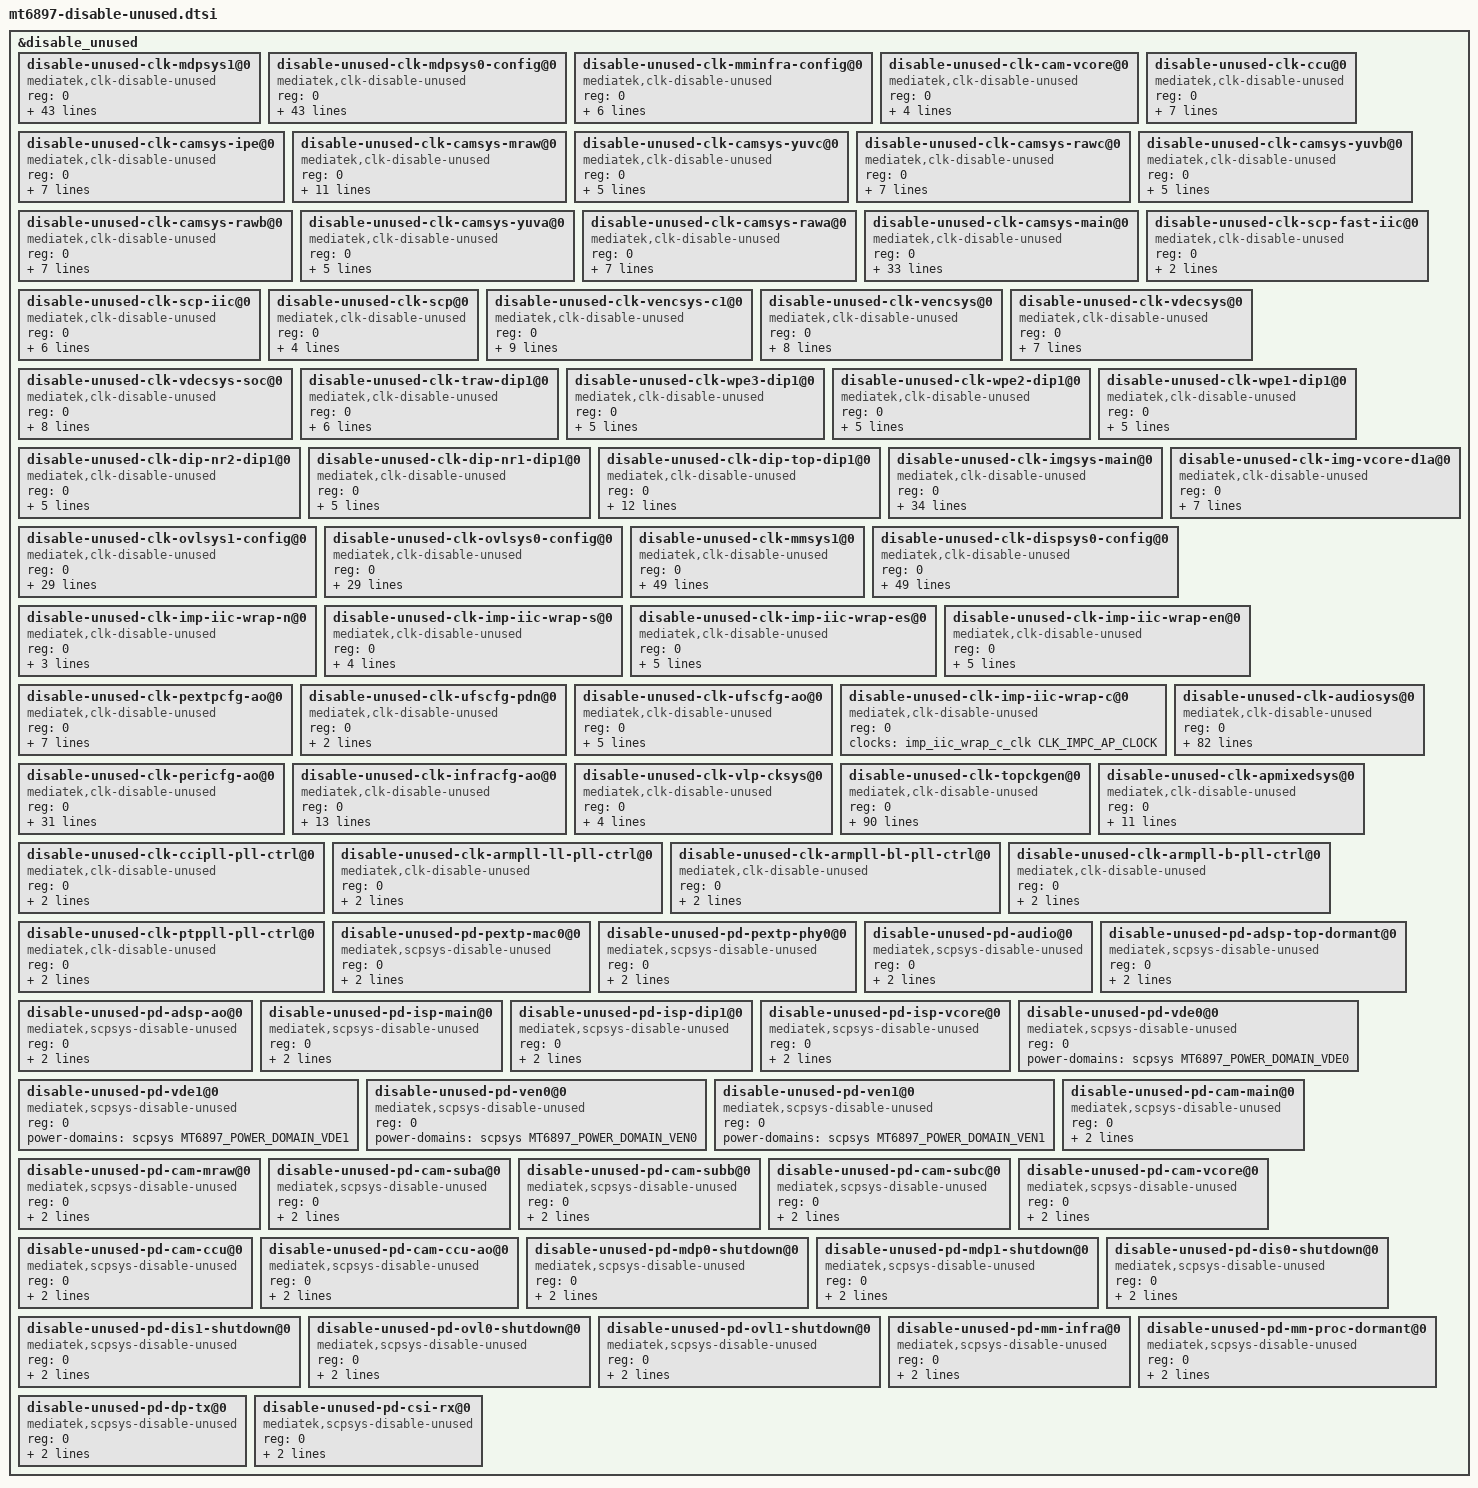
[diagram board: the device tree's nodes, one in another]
// SPDX-License-Identifier: (GPL-2.0 OR MIT)
/*
 * Copyright (C) 2023 MediaTek Inc.
 * Author: Benjamin Chao <benjamin.chao@mediatek.com>
 */

&disable_unused {
	status = "okay";
	disable-unused-clk-mdpsys1@0 {
		compatible = "mediatek,clk-disable-unused";
		reg = <0>;
		clocks =
			<&mdpsys1_config_clk CLK_MDP1_MDP_MUTEX0>,
			<&mdpsys1_config_clk CLK_MDP1_APB_BUS>,
			<&mdpsys1_config_clk CLK_MDP1_SMI0>,
			<&mdpsys1_config_clk CLK_MDP1_MDP_RDMA0>,
			<&mdpsys1_config_clk CLK_MDP1_MDP_RDMA2>,
			<&mdpsys1_config_clk CLK_MDP1_MDP_HDR0>,
			<&mdpsys1_config_clk CLK_MDP1_MDP_AAL0>,
			<&mdpsys1_config_clk CLK_MDP1_MDP_RSZ0>,
			<&mdpsys1_config_clk CLK_MDP1_MDP_TDSHP0>,
			<&mdpsys1_config_clk CLK_MDP1_MDP_COLOR0>,
			<&mdpsys1_config_clk CLK_MDP1_MDP_WROT0>,
			<&mdpsys1_config_clk CLK_MDP1_MDP_FAKE_ENG0>,
			<&mdpsys1_config_clk CLK_MDP1_MDP_DLI_ASYNC0>,
			<&mdpsys1_config_clk CLK_MDP1_MDP_DLI_ASYNC1>,
			<&mdpsys1_config_clk CLK_MDP1_MDPSYS_CONFIG>,
			<&mdpsys1_config_clk CLK_MDP1_MDP_RDMA1>,
			<&mdpsys1_config_clk CLK_MDP1_MDP_RDMA3>,
			<&mdpsys1_config_clk CLK_MDP1_MDP_HDR1>,
			<&mdpsys1_config_clk CLK_MDP1_MDP_AAL1>,
			<&mdpsys1_config_clk CLK_MDP1_MDP_RSZ1>,
			<&mdpsys1_config_clk CLK_MDP1_MDP_TDSHP1>,
			<&mdpsys1_config_clk CLK_MDP1_MDP_COLOR1>,
			<&mdpsys1_config_clk CLK_MDP1_MDP_WROT1>,
			<&mdpsys1_config_clk CLK_MDP1_MDP_FG0>,
			<&mdpsys1_config_clk CLK_MDP1_MDP_RSZ2>,
			<&mdpsys1_config_clk CLK_MDP1_MDP_WROT2>,
			<&mdpsys1_config_clk CLK_MDP1_MDP_DLO_ASYNC0>,
			<&mdpsys1_config_clk CLK_MDP1_MDP_FG1>,
			<&mdpsys1_config_clk CLK_MDP1_MDP_RSZ3>,
			<&mdpsys1_config_clk CLK_MDP1_MDP_WROT3>,
			<&mdpsys1_config_clk CLK_MDP1_MDP_DLO_ASYNC1>,
			<&mdpsys1_config_clk CLK_MDP1_MDP_DLI_ASYNC2>,
			<&mdpsys1_config_clk CLK_MDP1_MDP_DLI_ASYNC3>,
			<&mdpsys1_config_clk CLK_MDP1_MDP_DLO_ASYNC2>,
			<&mdpsys1_config_clk CLK_MDP1_MDP_DLO_ASYNC3>,
			<&mdpsys1_config_clk CLK_MDP1_MDP_BIRSZ0>,
			<&mdpsys1_config_clk CLK_MDP1_MDP_BIRSZ1>,
			<&mdpsys1_config_clk CLK_MDP1_IMG_DL_ASYNC0>,
			<&mdpsys1_config_clk CLK_MDP1_IMG_DL_ASYNC1>,
			<&mdpsys1_config_clk CLK_MDP1_HRE_TOP_MDPSYS>;
			power-domains = <&scpsys MT6897_POWER_DOMAIN_MDP1_SHUTDOWN>;
	};

	disable-unused-clk-mdpsys0-config@0 {
		compatible = "mediatek,clk-disable-unused";
		reg = <0>;
		clocks =
			<&mdpsys0_config_clk CLK_MDP0_MDP_MUTEX0>,
			<&mdpsys0_config_clk CLK_MDP0_APB_BUS>,
			<&mdpsys0_config_clk CLK_MDP0_SMI0>,
			<&mdpsys0_config_clk CLK_MDP0_MDP_RDMA0>,
			<&mdpsys0_config_clk CLK_MDP0_MDP_RDMA2>,
			<&mdpsys0_config_clk CLK_MDP0_MDP_HDR0>,
			<&mdpsys0_config_clk CLK_MDP0_MDP_AAL0>,
			<&mdpsys0_config_clk CLK_MDP0_MDP_RSZ0>,
			<&mdpsys0_config_clk CLK_MDP0_MDP_TDSHP0>,
			<&mdpsys0_config_clk CLK_MDP0_MDP_COLOR0>,
			<&mdpsys0_config_clk CLK_MDP0_MDP_WROT0>,
			<&mdpsys0_config_clk CLK_MDP0_MDP_FAKE_ENG0>,
			<&mdpsys0_config_clk CLK_MDP0_MDP_DLI_ASYNC0>,
			<&mdpsys0_config_clk CLK_MDP0_MDP_DLI_ASYNC1>,
			<&mdpsys0_config_clk CLK_MDP0_MDPSYS_CONFIG>,
			<&mdpsys0_config_clk CLK_MDP0_MDP_RDMA1>,
			<&mdpsys0_config_clk CLK_MDP0_MDP_RDMA3>,
			<&mdpsys0_config_clk CLK_MDP0_MDP_HDR1>,
			<&mdpsys0_config_clk CLK_MDP0_MDP_AAL1>,
			<&mdpsys0_config_clk CLK_MDP0_MDP_RSZ1>,
			<&mdpsys0_config_clk CLK_MDP0_MDP_TDSHP1>,
			<&mdpsys0_config_clk CLK_MDP0_MDP_COLOR1>,
			<&mdpsys0_config_clk CLK_MDP0_MDP_WROT1>,
			<&mdpsys0_config_clk CLK_MDP0_MDP_FG0>,
			<&mdpsys0_config_clk CLK_MDP0_MDP_RSZ2>,
			<&mdpsys0_config_clk CLK_MDP0_MDP_WROT2>,
			<&mdpsys0_config_clk CLK_MDP0_MDP_DLO_ASYNC0>,
			<&mdpsys0_config_clk CLK_MDP0_MDP_FG1>,
			<&mdpsys0_config_clk CLK_MDP0_MDP_RSZ3>,
			<&mdpsys0_config_clk CLK_MDP0_MDP_WROT3>,
			<&mdpsys0_config_clk CLK_MDP0_MDP_DLO_ASYNC1>,
			<&mdpsys0_config_clk CLK_MDP0_MDP_DLI_ASYNC2>,
			<&mdpsys0_config_clk CLK_MDP0_MDP_DLI_ASYNC3>,
			<&mdpsys0_config_clk CLK_MDP0_MDP_DLO_ASYNC2>,
			<&mdpsys0_config_clk CLK_MDP0_MDP_DLO_ASYNC3>,
			<&mdpsys0_config_clk CLK_MDP0_MDP_BIRSZ0>,
			<&mdpsys0_config_clk CLK_MDP0_MDP_BIRSZ1>,
			<&mdpsys0_config_clk CLK_MDP0_IMG_DL_ASYNC0>,
			<&mdpsys0_config_clk CLK_MDP0_IMG_DL_ASYNC1>,
			<&mdpsys0_config_clk CLK_MDP0_HRE_TOP_MDPSYS>;
			power-domains = <&scpsys MT6897_POWER_DOMAIN_MDP0_SHUTDOWN>;
	};

	disable-unused-clk-mminfra-config@0 {
		compatible = "mediatek,clk-disable-unused";
		reg = <0>;
		clocks =
			<&mminfra_config_clk CLK_MMINFRA_GCE_D>,
			<&mminfra_config_clk CLK_MMINFRA_GCE_M>,
			<&mminfra_config_clk CLK_MMINFRA_SMI>,
			<&mminfra_config_clk CLK_MMINFRA_GCE_26M>;
			power-domains = <&scpsys MT6897_POWER_DOMAIN_MM_INFRA>;
	};

	disable-unused-clk-cam-vcore@0 {
		compatible = "mediatek,clk-disable-unused";
		reg = <0>;
		clocks =
			<&cam_vcore_clk CLK_CAM_VCORE_MM0_SUBCOMMON_DCM_DIS>;
		power-domains = <&scpsys MT6897_POWER_DOMAIN_CAM_VCORE>;
	};

	disable-unused-clk-ccu@0 {
		compatible = "mediatek,clk-disable-unused";
		reg = <0>;
		clocks =
			<&ccu_main_clk CLK_CCU_LARB30_CON>,
			<&ccu_main_clk CLK_CCU_AHB_CON>,
			<&ccu_main_clk CLK_CCUSYS_CCU0_CON>,
			<&ccu_main_clk CLK_CCUSYS_CCU1_CON>,
			<&ccu_main_clk CLK_CCU2MM0_GALS_CON>;
			power-domains = <&scpsys MT6897_POWER_DOMAIN_CAM_CCU>;
	};

	disable-unused-clk-camsys-ipe@0 {
		compatible = "mediatek,clk-disable-unused";
		reg = <0>;
		clocks =
			<&camsys_ipe_clk CLK_CAMSYS_IPE_LARB19>,
			<&camsys_ipe_clk CLK_CAMSYS_IPE_DPE>,
			<&camsys_ipe_clk CLK_CAMSYS_IPE_FUS>,
			<&camsys_ipe_clk CLK_CAMSYS_IPE_DHZE>,
			<&camsys_ipe_clk CLK_CAMSYS_IPE_GALS>;
			power-domains = <&scpsys MT6897_POWER_DOMAIN_CAM_MRAW>;
	};

	disable-unused-clk-camsys-mraw@0 {
		compatible = "mediatek,clk-disable-unused";
		reg = <0>;
		clocks =
			<&camsys_mraw_clk CLK_CAM_MR_LARBX>,
			<&camsys_mraw_clk CLK_CAM_MR_GALS>,
			<&camsys_mraw_clk CLK_CAM_MR_CAMTG>,
			<&camsys_mraw_clk CLK_CAM_MR_MRAW0>,
			<&camsys_mraw_clk CLK_CAM_MR_MRAW1>,
			<&camsys_mraw_clk CLK_CAM_MR_MRAW2>,
			<&camsys_mraw_clk CLK_CAM_MR_MRAW3>,
			<&camsys_mraw_clk CLK_CAM_MR_PDA0>,
			<&camsys_mraw_clk CLK_CAM_MR_PDA1>;
			power-domains = <&scpsys MT6897_POWER_DOMAIN_CAM_MRAW>;
	};

	disable-unused-clk-camsys-yuvc@0 {
		compatible = "mediatek,clk-disable-unused";
		reg = <0>;
		clocks =
			<&camsys_yuvc_clk CLK_CAM_YC_LARBX>,
			<&camsys_yuvc_clk CLK_CAM_YC_CAM>,
			<&camsys_yuvc_clk CLK_CAM_YC_CAMTG>;
			power-domains = <&scpsys MT6897_POWER_DOMAIN_CAM_SUBC>;
	};

	disable-unused-clk-camsys-rawc@0 {
		compatible = "mediatek,clk-disable-unused";
		reg = <0>;
		clocks =
			<&camsys_rawc_clk CLK_CAM_RC_LARBX>,
			<&camsys_rawc_clk CLK_CAM_RC_CAM>,
			<&camsys_rawc_clk CLK_CAM_RC_CAMTG>,
			<&camsys_rawc_clk CLK_CAM_RC_RAW2MM_GALS>,
			<&camsys_rawc_clk CLK_CAM_RC_YUV2RAW2MM_GALS>;
			power-domains = <&scpsys MT6897_POWER_DOMAIN_CAM_SUBC>;
	};

	disable-unused-clk-camsys-yuvb@0 {
		compatible = "mediatek,clk-disable-unused";
		reg = <0>;
		clocks =
			<&camsys_yuvb_clk CLK_CAM_YB_LARBX>,
			<&camsys_yuvb_clk CLK_CAM_YB_CAM>,
			<&camsys_yuvb_clk CLK_CAM_YB_CAMTG>;
			power-domains = <&scpsys MT6897_POWER_DOMAIN_CAM_SUBB>;
	};

	disable-unused-clk-camsys-rawb@0 {
		compatible = "mediatek,clk-disable-unused";
		reg = <0>;
		clocks =
			<&camsys_rawb_clk CLK_CAM_RB_LARBX>,
			<&camsys_rawb_clk CLK_CAM_RB_CAM>,
			<&camsys_rawb_clk CLK_CAM_RB_CAMTG>,
			<&camsys_rawb_clk CLK_CAM_RB_RAW2MM_GALS>,
			<&camsys_rawb_clk CLK_CAM_RB_YUV2RAW2MM_GALS>;
			power-domains = <&scpsys MT6897_POWER_DOMAIN_CAM_SUBB>;
	};

	disable-unused-clk-camsys-yuva@0 {
		compatible = "mediatek,clk-disable-unused";
		reg = <0>;
		clocks =
			<&camsys_yuva_clk CLK_CAM_YA_LARBX>,
			<&camsys_yuva_clk CLK_CAM_YA_CAM>,
			<&camsys_yuva_clk CLK_CAM_YA_CAMTG>;
			power-domains = <&scpsys MT6897_POWER_DOMAIN_CAM_SUBA>;
	};

	disable-unused-clk-camsys-rawa@0 {
		compatible = "mediatek,clk-disable-unused";
		reg = <0>;
		clocks =
			<&camsys_rawa_clk CLK_CAM_RA_LARBX>,
			<&camsys_rawa_clk CLK_CAM_RA_CAM>,
			<&camsys_rawa_clk CLK_CAM_RA_CAMTG>,
			<&camsys_rawa_clk CLK_CAM_RA_RAW2MM_GALS>,
			<&camsys_rawa_clk CLK_CAM_RA_YUV2RAW2MM_GALS>;
			power-domains = <&scpsys MT6897_POWER_DOMAIN_CAM_SUBA>;
	};

	disable-unused-clk-camsys-main@0 {
		compatible = "mediatek,clk-disable-unused";
		reg = <0>;
		clocks =
			<&camsys_main_clk CLK_CAM_MAIN_LARB13_CON_0>,
			<&camsys_main_clk CLK_CAM_MAIN_LARB14_CON_0>,
			<&camsys_main_clk CLK_CAM_MAIN_LARB27_CON_0>,
			<&camsys_main_clk CLK_CAM_MAIN_LARB29_CON_0>,
			<&camsys_main_clk CLK_CAM_MAIN_CAM_CON_0>,
			<&camsys_main_clk CLK_CAM_MAIN_CAM_SUBA_CON_0>,
			<&camsys_main_clk CLK_CAM_MAIN_CAM_SUBB_CON_0>,
			<&camsys_main_clk CLK_CAM_MAIN_CAM_SUBC_CON_0>,
			<&camsys_main_clk CLK_CAM_MAIN_CAM_MRAW_CON_0>,
			<&camsys_main_clk CLK_CAM_MAIN_CAMTG_CON_0>,
			<&camsys_main_clk CLK_CAM_MAIN_SENINF_CON_0>,
			<&camsys_main_clk CLK_CAM_MAIN_CAMSV_TOP_CON_0>,
			<&camsys_main_clk CLK_CAM_MAIN_ADLRD_CON_0>,
			<&camsys_main_clk CLK_CAM_MAIN_ADLWR_CON_0>,
			<&camsys_main_clk CLK_CAM_MAIN_UISP_CON_0>,
			<&camsys_main_clk CLK_CAM_MAIN_FAKE_ENG_CON_0>,
			<&camsys_main_clk CLK_CAM_MAIN_CAM2MM0_GALS_CON_0>,
			<&camsys_main_clk CLK_CAM_MAIN_CAM2MM1_GALS_CON_0>,
			<&camsys_main_clk CLK_CAM_MAIN_CAM2SYS_GALS_CON_0>,
			<&camsys_main_clk CLK_CAM_MAIN_CAM2MM2_GALS_CON_0>,
			<&camsys_main_clk CLK_CAM_MAIN_CCUSYS_CON_0>,
			<&camsys_main_clk CLK_CAM_MAIN_IPS_CON_0>,
			<&camsys_main_clk CLK_CAM_MAIN_CAM_DPE_CON_0>,
			<&camsys_main_clk CLK_CAM_MAIN_CAM_ASG_CON_0>,
			<&camsys_main_clk CLK_CAM_MAIN_CAMSV_A_CON_1>,
			<&camsys_main_clk CLK_CAM_MAIN_CAMSV_B_CON_1>,
			<&camsys_main_clk CLK_CAM_MAIN_CAMSV_C_CON_1>,
			<&camsys_main_clk CLK_CAM_MAIN_CAMSV_D_CON_1>,
			<&camsys_main_clk CLK_CAM_MAIN_CAMSV_E_CON_1>,
			<&camsys_main_clk CLK_CAM_MAIN_CAMSV_CON_1>;
			power-domains = <&scpsys MT6897_POWER_DOMAIN_CAM_MAIN>;
	};

	disable-unused-clk-scp-fast-iic@0 {
		compatible = "mediatek,clk-disable-unused";
		reg = <0>;
		clocks =
			<&scp_fast_iic_clk CLK_SCP_FAST_IIC_AP_CLOCK_I2C0>;
	};

	disable-unused-clk-scp-iic@0 {
		compatible = "mediatek,clk-disable-unused";
		reg = <0>;
		clocks =
			<&scp_iic_clk CLK_SCP_IIC_AP_CLOCK_I2C1>,
			<&scp_iic_clk CLK_SCP_IIC_AP_CLOCK_I2C2>,
			<&scp_iic_clk CLK_SCP_IIC_AP_CLOCK_I2C3>,
			<&scp_iic_clk CLK_SCP_IIC_AP_CLOCK_I2C4>,
			<&scp_iic_clk CLK_SCP_IIC_AP_CLOCK_I2C5>,
			<&scp_iic_clk CLK_SCP_IIC_AP_CLOCK_I2C6>;
	};

	disable-unused-clk-scp@0 {
		compatible = "mediatek,clk-disable-unused";
		reg = <0>;
		clocks =
			<&scp_clk CLK_SCP_SET_SPI0>,
			<&scp_clk CLK_SCP_SET_SPI1>,
			<&scp_clk CLK_SCP_SET_SPI2>,
			<&scp_clk CLK_SCP_SET_SPI3>;
	};

	disable-unused-clk-vencsys-c1@0 {
		compatible = "mediatek,clk-disable-unused";
		reg = <0>;
		clocks =
			<&venc_gcon_core1_clk CLK_VEN2_CKE0_LARB>,
			<&venc_gcon_core1_clk CLK_VEN2_CKE1_VENC>,
			<&venc_gcon_core1_clk CLK_VEN2_CKE2_JPGENC>,
			<&venc_gcon_core1_clk CLK_VEN2_CKE3_JPGDEC>,
			<&venc_gcon_core1_clk CLK_VEN2_CKE4_JPGDEC_C1>,
			<&venc_gcon_core1_clk CLK_VEN2_CKE5_GALS>,
			<&venc_gcon_core1_clk CLK_VEN2_CKE6_GALS_SRAM>;
			power-domains = <&scpsys MT6897_POWER_DOMAIN_VEN1>;
	};

	disable-unused-clk-vencsys@0 {
		compatible = "mediatek,clk-disable-unused";
		reg = <0>;
		clocks =
			<&venc_gcon_clk CLK_VEN1_CKE0_LARB>,
			<&venc_gcon_clk CLK_VEN1_CKE1_VENC>,
			<&venc_gcon_clk CLK_VEN1_CKE2_JPGENC>,
			<&venc_gcon_clk CLK_VEN1_CKE3_JPGDEC>,
			<&venc_gcon_clk CLK_VEN1_CKE4_JPGDEC_C1>,
			<&venc_gcon_clk CLK_VEN1_CKE5_GALS>,
			<&venc_gcon_clk CLK_VEN1_CKE6_GALS_SRAM>;
			power-domains = <&scpsys MT6897_POWER_DOMAIN_VEN0>;
	};

	disable-unused-clk-vdecsys@0 {
		compatible = "mediatek,clk-disable-unused";
		reg = <0>;
		clocks =
			<&vdec_gcon_base_clk CLK_VDE2_LAT_CKEN>,
			<&vdec_gcon_base_clk CLK_VDE2_LAT_ACTIVE>,
			<&vdec_gcon_base_clk CLK_VDE2_LAT_CKEN_ENG>,
			<&vdec_gcon_base_clk CLK_VDE2_VDEC_CKEN>,
			<&vdec_gcon_base_clk CLK_VDE2_VDEC_ACTIVE>,
			<&vdec_gcon_base_clk CLK_VDE2_VDEC_CKEN_ENG>;
			power-domains = <&scpsys MT6897_POWER_DOMAIN_VDE1>;
	};

	disable-unused-clk-vdecsys-soc@0 {
		compatible = "mediatek,clk-disable-unused";
		reg = <0>;
		clocks =
			<&vdec_soc_gcon_base_clk CLK_VDE1_LAT_CKEN>,
			<&vdec_soc_gcon_base_clk CLK_VDE1_LAT_ACTIVE>,
			<&vdec_soc_gcon_base_clk CLK_VDE1_LAT_CKEN_ENG>,
			<&vdec_soc_gcon_base_clk CLK_VDE1_VDEC_CKEN>,
			<&vdec_soc_gcon_base_clk CLK_VDE1_VDEC_ACTIVE>,
			<&vdec_soc_gcon_base_clk CLK_VDE1_VDEC_CKEN_ENG>;
			power-domains = <&scpsys MT6897_POWER_DOMAIN_VDE0>;
	};

	disable-unused-clk-traw-dip1@0 {
		compatible = "mediatek,clk-disable-unused";
		reg = <0>;
		clocks =
			<&traw_dip1_clk CLK_TRAW_DIP1_LARB28>,
			<&traw_dip1_clk CLK_TRAW_DIP1_LARB40>,
			<&traw_dip1_clk CLK_TRAW_DIP1_TRAW>,
			<&traw_dip1_clk CLK_TRAW_DIP1_GALS>;
			power-domains = <&scpsys MT6897_POWER_DOMAIN_ISP_DIP1>;
	};

	disable-unused-clk-wpe3-dip1@0 {
		compatible = "mediatek,clk-disable-unused";
		reg = <0>;
		clocks =
			<&wpe3_dip1_clk CLK_WPE3_DIP1_LARB11>,
			<&wpe3_dip1_clk CLK_WPE3_DIP1_WPE>,
			<&wpe3_dip1_clk CLK_WPE3_DIP1_GALS0>;
			power-domains = <&scpsys MT6897_POWER_DOMAIN_ISP_DIP1>;
	};

	disable-unused-clk-wpe2-dip1@0 {
		compatible = "mediatek,clk-disable-unused";
		reg = <0>;
		clocks =
			<&wpe2_dip1_clk CLK_WPE2_DIP1_LARB11>,
			<&wpe2_dip1_clk CLK_WPE2_DIP1_WPE>,
			<&wpe2_dip1_clk CLK_WPE2_DIP1_GALS0>;
			power-domains = <&scpsys MT6897_POWER_DOMAIN_ISP_DIP1>;
	};

	disable-unused-clk-wpe1-dip1@0 {
		compatible = "mediatek,clk-disable-unused";
		reg = <0>;
		clocks =
			<&wpe1_dip1_clk CLK_WPE1_DIP1_LARB11>,
			<&wpe1_dip1_clk CLK_WPE1_DIP1_WPE>,
			<&wpe1_dip1_clk CLK_WPE1_DIP1_GALS0>;
			power-domains = <&scpsys MT6897_POWER_DOMAIN_ISP_DIP1>;
	};

	disable-unused-clk-dip-nr2-dip1@0 {
		compatible = "mediatek,clk-disable-unused";
		reg = <0>;
		clocks =
			<&dip_nr2_dip1_clk CLK_DIP_NR2_DIP1_LARB15>,
			<&dip_nr2_dip1_clk CLK_DIP_NR2_DIP1_DIP_NR>;
			power-domains = <&scpsys MT6897_POWER_DOMAIN_ISP_DIP1>;
	};

	disable-unused-clk-dip-nr1-dip1@0 {
		compatible = "mediatek,clk-disable-unused";
		reg = <0>;
		clocks =
			<&dip_nr1_dip1_clk CLK_DIP_NR1_DIP1_LARB>,
			<&dip_nr1_dip1_clk CLK_DIP_NR1_DIP1_DIP_NR1>;
			power-domains = <&scpsys MT6897_POWER_DOMAIN_ISP_DIP1>;
	};

	disable-unused-clk-dip-top-dip1@0 {
		compatible = "mediatek,clk-disable-unused";
		reg = <0>;
		clocks =
			<&dip_top_dip1_clk CLK_DIP_TOP_DIP1_DIP_TOP>,
			<&dip_top_dip1_clk CLK_DIP_TOP_DIP1_DIP_TOP_GALS0>,
			<&dip_top_dip1_clk CLK_DIP_TOP_DIP1_DIP_TOP_GALS1>,
			<&dip_top_dip1_clk CLK_DIP_TOP_DIP1_DIP_TOP_GALS2>,
			<&dip_top_dip1_clk CLK_DIP_TOP_DIP1_DIP_TOP_GALS3>,
			<&dip_top_dip1_clk CLK_DIP_TOP_DIP1_LARB10>,
			<&dip_top_dip1_clk CLK_DIP_TOP_DIP1_LARB15>,
			<&dip_top_dip1_clk CLK_DIP_TOP_DIP1_LARB38>,
			<&dip_top_dip1_clk CLK_DIP_TOP_DIP1_LARB39>;
			power-domains = <&scpsys MT6897_POWER_DOMAIN_ISP_DIP1>;
	};

	disable-unused-clk-imgsys-main@0 {
		compatible = "mediatek,clk-disable-unused";
		reg = <0>;
		clocks =
			<&imgsys_main_clk CLK_IMG_FDVT>,
			<&imgsys_main_clk CLK_IMG_ME>,
			<&imgsys_main_clk CLK_IMG_MMG>,
			<&imgsys_main_clk CLK_IMG_LARB12>,
			<&imgsys_main_clk CLK_IMG_LARB9>,
			<&imgsys_main_clk CLK_IMG_TRAW0>,
			<&imgsys_main_clk CLK_IMG_TRAW1>,
			<&imgsys_main_clk CLK_IMG_DIP0>,
			<&imgsys_main_clk CLK_IMG_WPE0>,
			<&imgsys_main_clk CLK_IMG_IPE>,
			<&imgsys_main_clk CLK_IMG_WPE1>,
			<&imgsys_main_clk CLK_IMG_WPE2>,
			<&imgsys_main_clk CLK_IMG_ADL_LARB>,
			<&imgsys_main_clk CLK_IMG_ADLRD>,
			<&imgsys_main_clk CLK_IMG_AVS>,
			<&imgsys_main_clk CLK_IMG_IPS>,
			<&imgsys_main_clk CLK_IMG_SUB_COMMON0>,
			<&imgsys_main_clk CLK_IMG_SUB_COMMON1>,
			<&imgsys_main_clk CLK_IMG_SUB_COMMON2>,
			<&imgsys_main_clk CLK_IMG_SUB_COMMON3>,
			<&imgsys_main_clk CLK_IMG_SUB_COMMON4>,
			<&imgsys_main_clk CLK_IMG_GALS_RX_DIP0>,
			<&imgsys_main_clk CLK_IMG_GALS_RX_DIP1>,
			<&imgsys_main_clk CLK_IMG_GALS_RX_TRAW0>,
			<&imgsys_main_clk CLK_IMG_GALS_RX_WPE0>,
			<&imgsys_main_clk CLK_IMG_GALS_RX_WPE1>,
			<&imgsys_main_clk CLK_IMG_GALS_RX_WPE2>,
			<&imgsys_main_clk CLK_IMG_GALS_RX_IPE0>,
			<&imgsys_main_clk CLK_IMG_GALS_TX_IPE0>,
			<&imgsys_main_clk CLK_IMG_GALS_RX_IPE1>,
			<&imgsys_main_clk CLK_IMG_GALS_TX_IPE1>,
			<&imgsys_main_clk CLK_IMG_GALS>;
			power-domains = <&scpsys MT6897_POWER_DOMAIN_ISP_MAIN>;
	};

	disable-unused-clk-img-vcore-d1a@0 {
		compatible = "mediatek,clk-disable-unused";
		reg = <0>;
		clocks =
			<&img_vcore_d1a_clk CLK_IMGV_IMG_VCORE_GALS_DISP_CON_0>,
			<&img_vcore_d1a_clk CLK_IMGV_IMG_VCORE_MAIN_CON_0>,
			<&img_vcore_d1a_clk CLK_IMGV_IMG_VCORE_SUB0_CON_0>,
			<&img_vcore_d1a_clk CLK_IMGV_IMG_VCORE_SUB1_CON_0>;
			power-domains = <&scpsys MT6897_POWER_DOMAIN_ISP_MAIN>;
	};


	disable-unused-clk-ovlsys1-config@0 {
		compatible = "mediatek,clk-disable-unused";
		reg = <0>;
		clocks =
			<&ovlsys1_config_clk CLK_OVLSYS1_CONFIG>,
			<&ovlsys1_config_clk CLK_OVLSYS1_DISP_FAKE_ENG0>,
			<&ovlsys1_config_clk CLK_OVLSYS1_DISP_FAKE_ENG1>,
			<&ovlsys1_config_clk CLK_OVLSYS1_DISP_MUTEX0>,
			<&ovlsys1_config_clk CLK_OVLSYS1_OVL0_2L>,
			<&ovlsys1_config_clk CLK_OVLSYS1_OVL1_2L>,
			<&ovlsys1_config_clk CLK_OVLSYS1_OVL2_2L>,
			<&ovlsys1_config_clk CLK_OVLSYS1_OVL3_2L>,
			<&ovlsys1_config_clk CLK_OVLSYS1_DISP_RSZ1>,
			<&ovlsys1_config_clk CLK_OVLSYS1_MDP_RSZ0>,
			<&ovlsys1_config_clk CLK_OVLSYS1_DISP_WDMA0>,
			<&ovlsys1_config_clk CLK_OVLSYS1_DISP_UFBC_WDMA0>,
			<&ovlsys1_config_clk CLK_OVLSYS1_DISP_WDMA2>,
			<&ovlsys1_config_clk CLK_OVLSYS1_DISP_DLI_ASYNC0>,
			<&ovlsys1_config_clk CLK_OVLSYS1_DISP_DLI_ASYNC1>,
			<&ovlsys1_config_clk CLK_OVLSYS1_DISP_DLI_ASYNC2>,
			<&ovlsys1_config_clk CLK_OVLSYS1_DISP_DLO_ASYNC0>,
			<&ovlsys1_config_clk CLK_OVLSYS1_DISP_DLO_ASYNC1>,
			<&ovlsys1_config_clk CLK_OVLSYS1_DISP_DLO_ASYNC2>,
			<&ovlsys1_config_clk CLK_OVLSYS1_DISP_DLO_ASYNC3>,
			<&ovlsys1_config_clk CLK_OVLSYS1_DISP_DLO_ASYNC4>,
			<&ovlsys1_config_clk CLK_OVLSYS1_DISP_DLO_ASYNC5>,
			<&ovlsys1_config_clk CLK_OVLSYS1_DISP_DLO_ASYNC6>,
			<&ovlsys1_config_clk CLK_OVLSYS1_INLINEROT>,
			<&ovlsys1_config_clk CLK_OVLSYS1_SMI_SUB_COMMON0>,
			<&ovlsys1_config_clk CLK_OVLSYS1_DISP_Y2R0>,
			<&ovlsys1_config_clk CLK_OVLSYS1_DISP_Y2R1>;
			power-domains = <&scpsys MT6897_POWER_DOMAIN_OVL1_SHUTDOWN>;
	};

	disable-unused-clk-ovlsys0-config@0 {
		compatible = "mediatek,clk-disable-unused";
		reg = <0>;
		clocks =
			<&ovlsys0_config_clk CLK_OVLSYS0_CONFIG>,
			<&ovlsys0_config_clk CLK_OVLSYS0_DISP_FAKE_ENG0>,
			<&ovlsys0_config_clk CLK_OVLSYS0_DISP_FAKE_ENG1>,
			<&ovlsys0_config_clk CLK_OVLSYS0_DISP_MUTEX0>,
			<&ovlsys0_config_clk CLK_OVLSYS0_OVL0_2L>,
			<&ovlsys0_config_clk CLK_OVLSYS0_OVL1_2L>,
			<&ovlsys0_config_clk CLK_OVLSYS0_OVL2_2L>,
			<&ovlsys0_config_clk CLK_OVLSYS0_OVL3_2L>,
			<&ovlsys0_config_clk CLK_OVLSYS0_DISP_RSZ1>,
			<&ovlsys0_config_clk CLK_OVLSYS0_MDP_RSZ0>,
			<&ovlsys0_config_clk CLK_OVLSYS0_DISP_WDMA0>,
			<&ovlsys0_config_clk CLK_OVLSYS0_DISP_UFBC_WDMA0>,
			<&ovlsys0_config_clk CLK_OVLSYS0_DISP_WDMA2>,
			<&ovlsys0_config_clk CLK_OVLSYS0_DISP_DLI_ASYNC0>,
			<&ovlsys0_config_clk CLK_OVLSYS0_DISP_DLI_ASYNC1>,
			<&ovlsys0_config_clk CLK_OVLSYS0_DISP_DLI_ASYNC2>,
			<&ovlsys0_config_clk CLK_OVLSYS0_DISP_DLO_ASYNC0>,
			<&ovlsys0_config_clk CLK_OVLSYS0_DISP_DLO_ASYNC1>,
			<&ovlsys0_config_clk CLK_OVLSYS0_DISP_DLO_ASYNC2>,
			<&ovlsys0_config_clk CLK_OVLSYS0_DISP_DLO_ASYNC3>,
			<&ovlsys0_config_clk CLK_OVLSYS0_DISP_DLO_ASYNC4>,
			<&ovlsys0_config_clk CLK_OVLSYS0_DISP_DLO_ASYNC5>,
			<&ovlsys0_config_clk CLK_OVLSYS0_DISP_DLO_ASYNC6>,
			<&ovlsys0_config_clk CLK_OVLSYS0_INLINEROT>,
			<&ovlsys0_config_clk CLK_OVLSYS0_SMI_SUB_COMMON0>,
			<&ovlsys0_config_clk CLK_OVLSYS0_DISP_Y2R0>,
			<&ovlsys0_config_clk CLK_OVLSYS0_DISP_Y2R1>;
			power-domains = <&scpsys MT6897_POWER_DOMAIN_OVL0_SHUTDOWN>;
	};

	disable-unused-clk-mmsys1@0 {
		compatible = "mediatek,clk-disable-unused";
		reg = <0>;
		clocks =
			<&dispsys1_config_clk CLK_DISPSYS1_DISPSYS_CONFIG>,
			<&dispsys1_config_clk CLK_DISPSYS1_DISP_MUTEX0>,
			<&dispsys1_config_clk CLK_DISPSYS1_DISP_AAL0>,
			<&dispsys1_config_clk CLK_DISPSYS1_DISP_C3D0>,
			<&dispsys1_config_clk CLK_DISPSYS1_DISP_CCORR0>,
			<&dispsys1_config_clk CLK_DISPSYS1_DISP_CCORR1>,
			<&dispsys1_config_clk CLK_DISPSYS1_DISP_CHIST0>,
			<&dispsys1_config_clk CLK_DISPSYS1_DISP_CHIST1>,
			<&dispsys1_config_clk CLK_DISPSYS1_DISP_COLOR0>,
			<&dispsys1_config_clk CLK_DISPSYS1_DISP_DITHER0>,
			<&dispsys1_config_clk CLK_DISPSYS1_DISP_DITHER1>,
			<&dispsys1_config_clk CLK_DISPSYS1_DISP_DLI_ASYNC0>,
			<&dispsys1_config_clk CLK_DISPSYS1_DISP_DLI_ASYNC1>,
			<&dispsys1_config_clk CLK_DISPSYS1_DISP_DLI_ASYNC2>,
			<&dispsys1_config_clk CLK_DISPSYS1_DISP_DLI_ASYNC3>,
			<&dispsys1_config_clk CLK_DISPSYS1_DISP_DLI_ASYNC4>,
			<&dispsys1_config_clk CLK_DISPSYS1_DISP_DLI_ASYNC5>,
			<&dispsys1_config_clk CLK_DISPSYS1_DISP_DLO_ASYNC0>,
			<&dispsys1_config_clk CLK_DISPSYS1_DISP_DLO_ASYNC1>,
			<&dispsys1_config_clk CLK_DISPSYS1_DISP_DP_INTF0>,
			<&dispsys1_config_clk CLK_DISPSYS1_DISP_DSC_WRAP0>,
			<&dispsys1_config_clk CLK_DISPSYS1_DISP_DSI0>,
			<&dispsys1_config_clk CLK_DISPSYS1_DISP_GAMMA0>,
			<&dispsys1_config_clk CLK_DISPSYS1_MDP_AAL0>,
			<&dispsys1_config_clk CLK_DISPSYS1_MDP_RDMA0>,
			<&dispsys1_config_clk CLK_DISPSYS1_DISP_MERGE0>,
			<&dispsys1_config_clk CLK_DISPSYS1_DISP_MERGE1>,
			<&dispsys1_config_clk CLK_DISPSYS1_DISP_ODDMR0>,
			<&dispsys1_config_clk CLK_DISPSYS1_DISP_POSTALIGN0>,
			<&dispsys1_config_clk CLK_DISPSYS1_DISP_POSTMASK0>,
			<&dispsys1_config_clk CLK_DISPSYS1_DISP_RELAY0>,
			<&dispsys1_config_clk CLK_DISPSYS1_DISP_RSZ0>,
			<&dispsys1_config_clk CLK_DISPSYS1_DISP_SPR0>,
			<&dispsys1_config_clk CLK_DISPSYS1_DISP_TDSHP0>,
			<&dispsys1_config_clk CLK_DISPSYS1_DISP_TDSHP1>,
			<&dispsys1_config_clk CLK_DISPSYS1_DISP_UFBC_WDMA1>,
			<&dispsys1_config_clk CLK_DISPSYS1_DISP_VDCM0>,
			<&dispsys1_config_clk CLK_DISPSYS1_DISP_WDMA1>,
			<&dispsys1_config_clk CLK_DISPSYS1_SMI_SUB_COMM0>,
			<&dispsys1_config_clk CLK_DISPSYS1_DISP_Y2R0>,
			<&dispsys1_config_clk CLK_DISPSYS1_DISP_CCORR2>,
			<&dispsys1_config_clk CLK_DISPSYS1_DISP_CCORR3>,
			<&dispsys1_config_clk CLK_DISPSYS1_DISP_GAMMA1>,
			<&dispsys1_config_clk CLK_DISPSYS1_DSI_CLK>,
			<&dispsys1_config_clk CLK_DISPSYS1_DP_CLK>,
			<&dispsys1_config_clk CLK_DISPSYS1_26M_CLK>;
			power-domains = <&scpsys MT6897_POWER_DOMAIN_DIS1_SHUTDOWN>;
	};

	disable-unused-clk-dispsys0-config@0 {
		compatible = "mediatek,clk-disable-unused";
		reg = <0>;
		clocks =
			<&dispsys0_config_clk CLK_DISPSYS0_DISPSYS_CONFIG>,
			<&dispsys0_config_clk CLK_DISPSYS0_DISP_MUTEX0>,
			<&dispsys0_config_clk CLK_DISPSYS0_DISP_AAL0>,
			<&dispsys0_config_clk CLK_DISPSYS0_DISP_C3D0>,
			<&dispsys0_config_clk CLK_DISPSYS0_DISP_CCORR0>,
			<&dispsys0_config_clk CLK_DISPSYS0_DISP_CCORR1>,
			<&dispsys0_config_clk CLK_DISPSYS0_DISP_CHIST0>,
			<&dispsys0_config_clk CLK_DISPSYS0_DISP_CHIST1>,
			<&dispsys0_config_clk CLK_DISPSYS0_DISP_COLOR0>,
			<&dispsys0_config_clk CLK_DISPSYS0_DISP_DITHER0>,
			<&dispsys0_config_clk CLK_DISPSYS0_DISP_DITHER1>,
			<&dispsys0_config_clk CLK_DISPSYS0_DISP_DLI_ASYNC0>,
			<&dispsys0_config_clk CLK_DISPSYS0_DISP_DLI_ASYNC1>,
			<&dispsys0_config_clk CLK_DISPSYS0_DISP_DLI_ASYNC2>,
			<&dispsys0_config_clk CLK_DISPSYS0_DISP_DLI_ASYNC3>,
			<&dispsys0_config_clk CLK_DISPSYS0_DISP_DLI_ASYNC4>,
			<&dispsys0_config_clk CLK_DISPSYS0_DISP_DLI_ASYNC5>,
			<&dispsys0_config_clk CLK_DISPSYS0_DISP_DLO_ASYNC0>,
			<&dispsys0_config_clk CLK_DISPSYS0_DISP_DLO_ASYNC1>,
			<&dispsys0_config_clk CLK_DISPSYS0_DISP_DP_INTF0>,
			<&dispsys0_config_clk CLK_DISPSYS0_DISP_DSC_WRAP0>,
			<&dispsys0_config_clk CLK_DISPSYS0_DISP_DSI0>,
			<&dispsys0_config_clk CLK_DISPSYS0_DISP_GAMMA0>,
			<&dispsys0_config_clk CLK_DISPSYS0_MDP_AAL0>,
			<&dispsys0_config_clk CLK_DISPSYS0_MDP_RDMA0>,
			<&dispsys0_config_clk CLK_DISPSYS0_DISP_MERGE0>,
			<&dispsys0_config_clk CLK_DISPSYS0_DISP_MERGE1>,
			<&dispsys0_config_clk CLK_DISPSYS0_DISP_ODDMR0>,
			<&dispsys0_config_clk CLK_DISPSYS0_DISP_POSTALIGN0>,
			<&dispsys0_config_clk CLK_DISPSYS0_DISP_POSTMASK0>,
			<&dispsys0_config_clk CLK_DISPSYS0_DISP_RELAY0>,
			<&dispsys0_config_clk CLK_DISPSYS0_DISP_RSZ0>,
			<&dispsys0_config_clk CLK_DISPSYS0_DISP_SPR0>,
			<&dispsys0_config_clk CLK_DISPSYS0_DISP_TDSHP0>,
			<&dispsys0_config_clk CLK_DISPSYS0_DISP_TDSHP1>,
			<&dispsys0_config_clk CLK_DISPSYS0_DISP_UFBC_WDMA1>,
			<&dispsys0_config_clk CLK_DISPSYS0_DISP_VDCM0>,
			<&dispsys0_config_clk CLK_DISPSYS0_DISP_WDMA1>,
			<&dispsys0_config_clk CLK_DISPSYS0_SMI_SUB_COMM0>,
			<&dispsys0_config_clk CLK_DISPSYS0_DISP_Y2R0>,
			<&dispsys0_config_clk CLK_DISPSYS0_DISP_CCORR2>,
			<&dispsys0_config_clk CLK_DISPSYS0_DISP_CCORR3>,
			<&dispsys0_config_clk CLK_DISPSYS0_DISP_GAMMA1>,
			<&dispsys0_config_clk CLK_DISPSYS0_DSI_CLK>,
			<&dispsys0_config_clk CLK_DISPSYS0_DP_CLK>,
			<&dispsys0_config_clk CLK_DISPSYS0_26M_CLK>;
			power-domains = <&scpsys MT6897_POWER_DOMAIN_DIS0_SHUTDOWN>;
	};

	disable-unused-clk-imp-iic-wrap-n@0 {
		compatible = "mediatek,clk-disable-unused";
		reg = <0>;
		clocks =
			<&imp_iic_wrap_n_clk CLK_IMPN_AP_CLOCK_I2C3>,
			<&imp_iic_wrap_n_clk CLK_IMPN_AP_CLOCK_I2C5>;
	};

	disable-unused-clk-imp-iic-wrap-s@0 {
		compatible = "mediatek,clk-disable-unused";
		reg = <0>;
		clocks =
			<&imp_iic_wrap_s_clk CLK_IMPS_AP_CLOCK_I2C0>,
			<&imp_iic_wrap_s_clk CLK_IMPS_AP_CLOCK_I2C1>,
			<&imp_iic_wrap_s_clk CLK_IMPS_AP_CLOCK_I2C7>;
	};

	disable-unused-clk-imp-iic-wrap-es@0 {
		compatible = "mediatek,clk-disable-unused";
		reg = <0>;
		clocks =
			<&imp_iic_wrap_es_clk CLK_IMPES_AP_CLOCK_I2C8>,
			<&imp_iic_wrap_es_clk CLK_IMPES_AP_CLOCK_I2C9>,
			<&imp_iic_wrap_es_clk CLK_IMPES_AP_CLOCK_I2C12>,
			<&imp_iic_wrap_es_clk CLK_IMPES_AP_CLOCK_I2C13>;
	};

	disable-unused-clk-imp-iic-wrap-en@0 {
		compatible = "mediatek,clk-disable-unused";
		reg = <0>;
		clocks =
			<&imp_iic_wrap_en_clk CLK_IMPEN_AP_CLOCK_I2C2>,
			<&imp_iic_wrap_en_clk CLK_IMPEN_AP_CLOCK_I2C4>,
			<&imp_iic_wrap_en_clk CLK_IMPEN_AP_CLOCK_I2C10>,
			<&imp_iic_wrap_en_clk CLK_IMPEN_AP_CLOCK_I2C11>;
	};

	disable-unused-clk-pextpcfg-ao@0 {
		compatible = "mediatek,clk-disable-unused";
		reg = <0>;
		clocks =
			<&pextpcfg_ao_clk CLK_PEXTPCFG_AO_PEXTP_P0_MAC_REF>,
			<&pextpcfg_ao_clk CLK_PEXTPCFG_AO_PEXTP_P0_MAC_PL_PCLK>,
			<&pextpcfg_ao_clk CLK_PEXTPCFG_AO_PEXTP_P0_MAC_TL>,
			<&pextpcfg_ao_clk CLK_PEXTPCFG_AO_PEXTP_P0_MAC_AXI>,
			<&pextpcfg_ao_clk CLK_PEXTPCFG_AO_PEXTP_P0_MAC_AHB_APB>,
			<&pextpcfg_ao_clk CLK_PEXTPCFG_AO_PEXTP_P0_PHY_REF_CK>;
	};

	disable-unused-clk-ufscfg-pdn@0 {
		compatible = "mediatek,clk-disable-unused";
		reg = <0>;
		clocks =
			<&ufscfg_pdn_clk CLK_UFSCFG_UFSHCI_UFS>,
			<&ufscfg_pdn_clk CLK_UFSCFG_UFSHCI_AES>;
	};

	disable-unused-clk-ufscfg-ao@0 {
		compatible = "mediatek,clk-disable-unused";
		reg = <0>;
		clocks =
			<&ufscfg_ao_clk CLK_UFSCFG_AO_UNIPRO_TX_SYMBOLCLK>,
			<&ufscfg_ao_clk CLK_UFSCFG_AO_UNIPRO_RX_SYMBOLCLK0>,
			<&ufscfg_ao_clk CLK_UFSCFG_AO_UNIPRO_RX_SYMBOLCLK1>,
			<&ufscfg_ao_clk CLK_UFSCFG_AO_UNIPRO_SYSCLK>;
	};

	disable-unused-clk-imp-iic-wrap-c@0 {
		compatible = "mediatek,clk-disable-unused";
		reg = <0>;
		clocks =
			<&imp_iic_wrap_c_clk CLK_IMPC_AP_CLOCK>;
	};

	disable-unused-clk-audiosys@0 {
		compatible = "mediatek,clk-disable-unused";
		reg = <0>;
		clocks =
			<&afe_clk CLK_AFE_DL1_DAC_TML>,
			<&afe_clk CLK_AFE_DL1_DAC_HIRES>,
			<&afe_clk CLK_AFE_DL1_DAC>,
			<&afe_clk CLK_AFE_DL1_PREDIS>,
			<&afe_clk CLK_AFE_DL1_NLE>,
			<&afe_clk CLK_AFE_DL0_DAC_TML>,
			<&afe_clk CLK_AFE_DL0_DAC_HIRES>,
			<&afe_clk CLK_AFE_DL0_DAC>,
			<&afe_clk CLK_AFE_DL0_PREDIS>,
			<&afe_clk CLK_AFE_DL0_NLE>,
			<&afe_clk CLK_AFE_PCM1>,
			<&afe_clk CLK_AFE_PCM0>,
			<&afe_clk CLK_AFE_CM1>,
			<&afe_clk CLK_AFE_CM0>,
			<&afe_clk CLK_AFE_STF>,
			<&afe_clk CLK_AFE_HW_GAIN23>,
			<&afe_clk CLK_AFE_HW_GAIN01>,
			<&afe_clk CLK_AFE_FM_I2S>,
			<&afe_clk CLK_AFE_DMIC1_ADC_HIRES_TML>,
			<&afe_clk CLK_AFE_DMIC1_ADC_HIRES>,
			<&afe_clk CLK_AFE_DMIC1_TML>,
			<&afe_clk CLK_AFE_DMIC1_ADC>,
			<&afe_clk CLK_AFE_DMIC0_ADC_HIRES_TML>,
			<&afe_clk CLK_AFE_DMIC0_ADC_HIRES>,
			<&afe_clk CLK_AFE_DMIC0_TML>,
			<&afe_clk CLK_AFE_DMIC0_ADC>,
			<&afe_clk CLK_AFE_UL1_ADC_HIRES_TML>,
			<&afe_clk CLK_AFE_UL1_ADC_HIRES>,
			<&afe_clk CLK_AFE_UL1_TML>,
			<&afe_clk CLK_AFE_UL1_ADC>,
			<&afe_clk CLK_AFE_UL0_ADC_HIRES_TML>,
			<&afe_clk CLK_AFE_UL0_ADC_HIRES>,
			<&afe_clk CLK_AFE_UL0_TML>,
			<&afe_clk CLK_AFE_UL0_ADC>,
			<&afe_clk CLK_AFE_DPRX>,
			<&afe_clk CLK_AFE_DPTX>,
			<&afe_clk CLK_AFE_ETDM_IN6>,
			<&afe_clk CLK_AFE_ETDM_IN5>,
			<&afe_clk CLK_AFE_ETDM_IN4>,
			<&afe_clk CLK_AFE_ETDM_IN3>,
			<&afe_clk CLK_AFE_ETDM_IN2>,
			<&afe_clk CLK_AFE_ETDM_IN1>,
			<&afe_clk CLK_AFE_ETDM_IN0>,
			<&afe_clk CLK_AFE_ETDM_OUT6>,
			<&afe_clk CLK_AFE_ETDM_OUT5>,
			<&afe_clk CLK_AFE_ETDM_OUT4>,
			<&afe_clk CLK_AFE_ETDM_OUT3>,
			<&afe_clk CLK_AFE_ETDM_OUT2>,
			<&afe_clk CLK_AFE_ETDM_OUT1>,
			<&afe_clk CLK_AFE_ETDM_OUT0>,
			<&afe_clk CLK_AFE_GENERAL24_ASRC>,
			<&afe_clk CLK_AFE_GENERAL23_ASRC>,
			<&afe_clk CLK_AFE_GENERAL22_ASRC>,
			<&afe_clk CLK_AFE_GENERAL21_ASRC>,
			<&afe_clk CLK_AFE_GENERAL20_ASRC>,
			<&afe_clk CLK_AFE_GENERAL19_ASRC>,
			<&afe_clk CLK_AFE_GENERAL18_ASRC>,
			<&afe_clk CLK_AFE_GENERAL17_ASRC>,
			<&afe_clk CLK_AFE_GENERAL16_ASRC>,
			<&afe_clk CLK_AFE_GENERAL15_ASRC>,
			<&afe_clk CLK_AFE_GENERAL14_ASRC>,
			<&afe_clk CLK_AFE_GENERAL13_ASRC>,
			<&afe_clk CLK_AFE_GENERAL12_ASRC>,
			<&afe_clk CLK_AFE_GENERAL11_ASRC>,
			<&afe_clk CLK_AFE_GENERAL10_ASRC>,
			<&afe_clk CLK_AFE_GENERAL9_ASRC>,
			<&afe_clk CLK_AFE_GENERAL8_ASRC>,
			<&afe_clk CLK_AFE_GENERAL7_ASRC>,
			<&afe_clk CLK_AFE_GENERAL6_ASRC>,
			<&afe_clk CLK_AFE_GENERAL5_ASRC>,
			<&afe_clk CLK_AFE_GENERAL4_ASRC>,
			<&afe_clk CLK_AFE_GENERAL3_ASRC>,
			<&afe_clk CLK_AFE_GENERAL2_ASRC>,
			<&afe_clk CLK_AFE_GENERAL1_ASRC>,
			<&afe_clk CLK_AFE_GENERAL0_ASRC>,
			<&afe_clk CLK_AFE_CONNSYS_I2S_ASRC>,
			<&afe_clk CLK_AFE_AUDIO_HOPPING>,
			<&afe_clk CLK_AFE_AUDIO_F26M>,
			<&afe_clk CLK_AFE_APLL1>,
			<&afe_clk CLK_AFE_APLL2>,
			<&afe_clk CLK_AFE_H208M>,
			<&afe_clk CLK_AFE_APLL_TUNER2>,
			<&afe_clk CLK_AFE_APLL_TUNER1>;
			power-domains = <&scpsys MT6897_POWER_DOMAIN_AUDIO>;
	};

	disable-unused-clk-pericfg-ao@0 {
		compatible = "mediatek,clk-disable-unused";
		reg = <0>;
		clocks =
			<&pericfg_ao_clk CLK_PERAOP_UART0>,
			<&pericfg_ao_clk CLK_PERAOP_UART1>,
			<&pericfg_ao_clk CLK_PERAOP_UART2>,
			<&pericfg_ao_clk CLK_PERAOP_UART3>,
			<&pericfg_ao_clk CLK_PERAOP_PWM_HCLK>,
			<&pericfg_ao_clk CLK_PERAOP_PWM_BCLK>,
			<&pericfg_ao_clk CLK_PERAOP_PWM_FBCLK1>,
			<&pericfg_ao_clk CLK_PERAOP_PWM_FBCLK2>,
			<&pericfg_ao_clk CLK_PERAOP_PWM_FBCLK3>,
			<&pericfg_ao_clk CLK_PERAOP_PWM_FBCLK4>,
			<&pericfg_ao_clk CLK_PERAOP_DISP_PWM0>,
			<&pericfg_ao_clk CLK_PERAOP_DISP_PWM1>,
			<&pericfg_ao_clk CLK_PERAOP_SPI0_BCLK>,
			<&pericfg_ao_clk CLK_PERAOP_SPI1_BCLK>,
			<&pericfg_ao_clk CLK_PERAOP_SPI2_BCLK>,
			<&pericfg_ao_clk CLK_PERAOP_SPI3_BCLK>,
			<&pericfg_ao_clk CLK_PERAOP_SPI4_BCLK>,
			<&pericfg_ao_clk CLK_PERAOP_SPI5_BCLK>,
			<&pericfg_ao_clk CLK_PERAOP_SPI6_BCLK>,
			<&pericfg_ao_clk CLK_PERAOP_SPI7_BCLK>,
			<&pericfg_ao_clk CLK_PERAOP_DMA_BCLK>,
			<&pericfg_ao_clk CLK_PERAOP_SSUSB0_FRMCNT>,
			<&pericfg_ao_clk CLK_PERAOP_MSDC1>,
			<&pericfg_ao_clk CLK_PERAOP_MSDC1_FCLK>,
			<&pericfg_ao_clk CLK_PERAOP_MSDC1_HCLK>,
			<&pericfg_ao_clk CLK_PERAOP_MSDC2>,
			<&pericfg_ao_clk CLK_PERAOP_MSDC2_FCLK>,
			<&pericfg_ao_clk CLK_PERAOP_MSDC2_HCLK>,
			<&pericfg_ao_clk CLK_PERAOP_AUDIO_SLV_CK>,
			<&pericfg_ao_clk CLK_PERAOP_AUDIO_MST_CK>,
			<&pericfg_ao_clk CLK_PERAOP_AUDIO_INTBUS_CK>;
	};

	disable-unused-clk-infracfg-ao@0 {
		compatible = "mediatek,clk-disable-unused";
		reg = <0>;
		clocks =
			<&infracfg_ao_clk CLK_IFRAO_CQ_DMA_FPC>,
			<&infracfg_ao_clk CLK_IFRAO_CCIF1_AP>,
			<&infracfg_ao_clk CLK_IFRAO_CCIF1_MD>,
			<&infracfg_ao_clk CLK_IFRAO_CCIF_AP>,
			<&infracfg_ao_clk CLK_IFRAO_CCIF_MD>,
			<&infracfg_ao_clk CLK_IFRAO_CLDMA_BCLK>,
			<&infracfg_ao_clk CLK_IFRAO_CQ_DMA>,
			<&infracfg_ao_clk CLK_IFRAO_CCIF5_MD>,
			<&infracfg_ao_clk CLK_IFRAO_CCIF2_AP>,
			<&infracfg_ao_clk CLK_IFRAO_CCIF2_MD>,
			<&infracfg_ao_clk CLK_IFRAO_DPMAIF_MAIN>,
			<&infracfg_ao_clk CLK_IFRAO_CCIF4_MD>,
			<&infracfg_ao_clk CLK_IFRAO_RG_MMW_DPMAIF26M_CK>;
	};

	disable-unused-clk-vlp-cksys@0 {
		compatible = "mediatek,clk-disable-unused";
		reg = <0>;
		clocks =
			<&vlp_cksys_clk CLK_VLP_CK_SCP_SEL>,
			<&vlp_cksys_clk CLK_VLP_CK_CAMTG_SEL>,
			<&vlp_cksys_clk CLK_VLP_CK_CCUSYS_SEL>,
			<&vlp_cksys_clk CLK_VLP_CK_CCUTM_SEL>;
	};

	disable-unused-clk-topckgen@0 {
		compatible = "mediatek,clk-disable-unused";
		reg = <0>;
		clocks =
			<&topckgen_clk CLK_TOP_APLL12_CK_DIV_I2SIN0>,
			<&topckgen_clk CLK_TOP_APLL12_CK_DIV_I2SIN1>,
			<&topckgen_clk CLK_TOP_APLL12_CK_DIV_I2SIN2>,
			<&topckgen_clk CLK_TOP_APLL12_CK_DIV_I2SIN3>,
			<&topckgen_clk CLK_TOP_APLL12_CK_DIV_I2SIN4>,
			<&topckgen_clk CLK_TOP_APLL12_CK_DIV_I2SIN6>,
			<&topckgen_clk CLK_TOP_APLL12_CK_DIV_I2SOUT0>,
			<&topckgen_clk CLK_TOP_APLL12_CK_DIV_I2SOUT1>,
			<&topckgen_clk CLK_TOP_APLL12_CK_DIV_I2SOUT2>,
			<&topckgen_clk CLK_TOP_APLL12_CK_DIV_I2SOUT3>,
			<&topckgen_clk CLK_TOP_APLL12_CK_DIV_I2SOUT4>,
			<&topckgen_clk CLK_TOP_APLL12_CK_DIV_I2SOUT6>,
			<&topckgen_clk CLK_TOP_APLL12_CK_DIV_FMI2S>,
			<&topckgen_clk CLK_TOP_APLL12_CK_DIV_TDMOUT_M>,
			<&topckgen_clk CLK_TOP_APLL12_CK_DIV_TDMOUT_B>,
			<&topckgen_clk CLK_TOP_DISP0_SEL>,
			<&topckgen_clk CLK_TOP_DISP1_SEL>,
			<&topckgen_clk CLK_TOP_OVL0_SEL>,
			<&topckgen_clk CLK_TOP_OVL1_SEL>,
			<&topckgen_clk CLK_TOP_MDP0_SEL>,
			<&topckgen_clk CLK_TOP_MDP1_SEL>,
			<&topckgen_clk CLK_TOP_MMINFRA_SEL>,
			<&topckgen_clk CLK_TOP_CAMTG2_SEL>,
			<&topckgen_clk CLK_TOP_CAMTG3_SEL>,
			<&topckgen_clk CLK_TOP_CAMTG4_SEL>,
			<&topckgen_clk CLK_TOP_CAMTG5_SEL>,
			<&topckgen_clk CLK_TOP_CAMTG6_SEL>,
			<&topckgen_clk CLK_TOP_CAMTG7_SEL>,
			<&topckgen_clk CLK_TOP_CAMTG8_SEL>,
			<&topckgen_clk CLK_TOP_UART_SEL>,
			<&topckgen_clk CLK_TOP_MSDC_MACRO_1P_SEL>,
			<&topckgen_clk CLK_TOP_MSDC_MACRO_2P_SEL>,
			<&topckgen_clk CLK_TOP_MSDC30_1_SEL>,
			<&topckgen_clk CLK_TOP_MSDC30_2_SEL>,
			<&topckgen_clk CLK_TOP_AUD_INTBUS_SEL>,
			<&topckgen_clk CLK_TOP_DP_SEL>,
			<&topckgen_clk CLK_TOP_DISP_PWM_SEL>,
			<&topckgen_clk CLK_TOP_USB_TOP_SEL>,
			<&topckgen_clk CLK_TOP_USB_XHCI_SEL>,
			<&topckgen_clk CLK_TOP_I2C_SEL>,
			<&topckgen_clk CLK_TOP_SENINF_SEL>,
			<&topckgen_clk CLK_TOP_SENINF1_SEL>,
			<&topckgen_clk CLK_TOP_SENINF2_SEL>,
			<&topckgen_clk CLK_TOP_SENINF3_SEL>,
			<&topckgen_clk CLK_TOP_SENINF4_SEL>,
			<&topckgen_clk CLK_TOP_SENINF5_SEL>,
			<&topckgen_clk CLK_TOP_AUD_ENGEN1_SEL>,
			<&topckgen_clk CLK_TOP_AUD_ENGEN2_SEL>,
			<&topckgen_clk CLK_TOP_AES_UFSFDE_SEL>,
			<&topckgen_clk CLK_TOP_U_SEL>,
			<&topckgen_clk CLK_TOP_PEXTP_MBIST_SEL>,
			<&topckgen_clk CLK_TOP_AUD_1_SEL>,
			<&topckgen_clk CLK_TOP_AUD_2_SEL>,
			<&topckgen_clk CLK_TOP_ADSP_SEL>,
			<&topckgen_clk CLK_TOP_AUDIO_LOCAL_BUS_SEL>,
			<&topckgen_clk CLK_TOP_VENC_SEL>,
			<&topckgen_clk CLK_TOP_VDEC_SEL>,
			<&topckgen_clk CLK_TOP_PWM_SEL>,
			<&topckgen_clk CLK_TOP_AUDIO_H_SEL>,
			<&topckgen_clk CLK_TOP_CCU_AHB_SEL>,
			<&topckgen_clk CLK_TOP_IMG1_SEL>,
			<&topckgen_clk CLK_TOP_IPE_SEL>,
			<&topckgen_clk CLK_TOP_TL_SEL>,
			<&topckgen_clk CLK_TOP_SPI0_SEL>,
			<&topckgen_clk CLK_TOP_SPI1_SEL>,
			<&topckgen_clk CLK_TOP_SPI2_SEL>,
			<&topckgen_clk CLK_TOP_SPI3_SEL>,
			<&topckgen_clk CLK_TOP_SPI4_SEL>,
			<&topckgen_clk CLK_TOP_SPI5_SEL>,
			<&topckgen_clk CLK_TOP_SPI6_SEL>,
			<&topckgen_clk CLK_TOP_SPI7_SEL>,
			<&topckgen_clk CLK_TOP_MMUP_SEL>,
			<&topckgen_clk CLK_TOP_CAM_SEL>,
			<&topckgen_clk CLK_TOP_CAMTM_SEL>,
			<&topckgen_clk CLK_TOP_DPE_SEL>,
			<&topckgen_clk CLK_TOP_APLL_I2SIN0_MCK_SEL>,
			<&topckgen_clk CLK_TOP_APLL_I2SIN1_MCK_SEL>,
			<&topckgen_clk CLK_TOP_APLL_I2SIN2_MCK_SEL>,
			<&topckgen_clk CLK_TOP_APLL_I2SIN3_MCK_SEL>,
			<&topckgen_clk CLK_TOP_APLL_I2SIN4_MCK_SEL>,
			<&topckgen_clk CLK_TOP_APLL_I2SIN6_MCK_SEL>,
			<&topckgen_clk CLK_TOP_APLL_I2SOUT0_MCK_SEL>,
			<&topckgen_clk CLK_TOP_APLL_I2SOUT1_MCK_SEL>,
			<&topckgen_clk CLK_TOP_APLL_I2SOUT2_MCK_SEL>,
			<&topckgen_clk CLK_TOP_APLL_I2SOUT3_MCK_SEL>,
			<&topckgen_clk CLK_TOP_APLL_I2SOUT4_MCK_SEL>,
			<&topckgen_clk CLK_TOP_APLL_I2SOUT6_MCK_SEL>,
			<&topckgen_clk CLK_TOP_APLL_FMI2S_MCK_SEL>,
			<&topckgen_clk CLK_TOP_APLL_TDMOUT_MCK_SEL>;
	};

	disable-unused-clk-apmixedsys@0 {
		compatible = "mediatek,clk-disable-unused";
		reg = <0>;
		clocks =
			<&apmixedsys_clk CLK_APMIXED_MAINPLL>,
			<&apmixedsys_clk CLK_APMIXED_UNIVPLL>,
			<&apmixedsys_clk CLK_APMIXED_MSDCPLL>,
			<&apmixedsys_clk CLK_APMIXED_MMPLL>,
			<&apmixedsys_clk CLK_APMIXED_ADSPPLL>,
			<&apmixedsys_clk CLK_APMIXED_TVDPLL>,
			<&apmixedsys_clk CLK_APMIXED_APLL1>,
			<&apmixedsys_clk CLK_APMIXED_APLL2>,
			<&apmixedsys_clk CLK_APMIXED_MPLL>,
			<&apmixedsys_clk CLK_APMIXED_EMIPLL>,
			<&apmixedsys_clk CLK_APMIXED_IMGPLL>;
	};

	disable-unused-clk-ccipll-pll-ctrl@0 {
		compatible = "mediatek,clk-disable-unused";
		reg = <0>;
		clocks =
			<&ccipll_pll_ctrl_clk CLK_CCIPLL_PLL_CTRL_CCIPLL>;
	};

	disable-unused-clk-armpll-ll-pll-ctrl@0 {
		compatible = "mediatek,clk-disable-unused";
		reg = <0>;
		clocks =
			<&armpll_ll_pll_ctrl_clk CLK_ARMPLL_LL_PLL_CTRL_ARMPLL_LL>;
	};

	disable-unused-clk-armpll-bl-pll-ctrl@0 {
		compatible = "mediatek,clk-disable-unused";
		reg = <0>;
		clocks =
			<&armpll_bl_pll_ctrl_clk CLK_ARMPLL_BL_PLL_CTRL_ARMPLL_BL>;
	};

	disable-unused-clk-armpll-b-pll-ctrl@0 {
		compatible = "mediatek,clk-disable-unused";
		reg = <0>;
		clocks =
			<&armpll_b_pll_ctrl_clk CLK_ARMPLL_B_PLL_CTRL_ARMPLL_B>;
	};

	disable-unused-clk-ptppll-pll-ctrl@0 {
		compatible = "mediatek,clk-disable-unused";
		reg = <0>;
		clocks =
			<&ptppll_pll_ctrl_clk CLK_PTPPLL_PLL_CTRL_PTPPLL>;
	};

	disable-unused-pd-pextp-mac0@0 {
		compatible = "mediatek,scpsys-disable-unused";
		reg = <0>;
		power-domains = <&scpsys MT6897_POWER_DOMAIN_PEXTP_MAC0>;
	};

	disable-unused-pd-pextp-phy0@0 {
		compatible = "mediatek,scpsys-disable-unused";
		reg = <0>;
		power-domains = <&scpsys MT6897_POWER_DOMAIN_PEXTP_PHY0>;
	};

	disable-unused-pd-audio@0 {
		compatible = "mediatek,scpsys-disable-unused";
		reg = <0>;
		power-domains = <&scpsys MT6897_POWER_DOMAIN_AUDIO>;
	};

	disable-unused-pd-adsp-top-dormant@0 {
		compatible = "mediatek,scpsys-disable-unused";
		reg = <0>;
		power-domains = <&scpsys MT6897_POWER_DOMAIN_ADSP_TOP_DORMANT>;
	};

	disable-unused-pd-adsp-ao@0 {
		compatible = "mediatek,scpsys-disable-unused";
		reg = <0>;
		power-domains = <&scpsys MT6897_POWER_DOMAIN_ADSP_AO>;
	};

	disable-unused-pd-isp-main@0 {
		compatible = "mediatek,scpsys-disable-unused";
		reg = <0>;
		power-domains = <&scpsys MT6897_POWER_DOMAIN_ISP_MAIN>;
	};

	disable-unused-pd-isp-dip1@0 {
		compatible = "mediatek,scpsys-disable-unused";
		reg = <0>;
		power-domains = <&scpsys MT6897_POWER_DOMAIN_ISP_DIP1>;
	};

	disable-unused-pd-isp-vcore@0 {
		compatible = "mediatek,scpsys-disable-unused";
		reg = <0>;
		power-domains = <&scpsys MT6897_POWER_DOMAIN_ISP_VCORE>;
	};

	disable-unused-pd-vde0@0 {
		compatible = "mediatek,scpsys-disable-unused";
		reg = <0>;
		power-domains = <&scpsys MT6897_POWER_DOMAIN_VDE0>;
	};

	disable-unused-pd-vde1@0 {
		compatible = "mediatek,scpsys-disable-unused";
		reg = <0>;
		power-domains = <&scpsys MT6897_POWER_DOMAIN_VDE1>;
	};

	disable-unused-pd-ven0@0 {
		compatible = "mediatek,scpsys-disable-unused";
		reg = <0>;
		power-domains = <&scpsys MT6897_POWER_DOMAIN_VEN0>;
	};

	disable-unused-pd-ven1@0 {
		compatible = "mediatek,scpsys-disable-unused";
		reg = <0>;
		power-domains = <&scpsys MT6897_POWER_DOMAIN_VEN1>;
	};

	disable-unused-pd-cam-main@0 {
		compatible = "mediatek,scpsys-disable-unused";
		reg = <0>;
		power-domains = <&scpsys MT6897_POWER_DOMAIN_CAM_MAIN>;
	};

	disable-unused-pd-cam-mraw@0 {
		compatible = "mediatek,scpsys-disable-unused";
		reg = <0>;
		power-domains = <&scpsys MT6897_POWER_DOMAIN_CAM_MRAW>;
	};

	disable-unused-pd-cam-suba@0 {
		compatible = "mediatek,scpsys-disable-unused";
		reg = <0>;
		power-domains = <&scpsys MT6897_POWER_DOMAIN_CAM_SUBA>;
	};

	disable-unused-pd-cam-subb@0 {
		compatible = "mediatek,scpsys-disable-unused";
		reg = <0>;
		power-domains = <&scpsys MT6897_POWER_DOMAIN_CAM_SUBB>;
	};

	disable-unused-pd-cam-subc@0 {
		compatible = "mediatek,scpsys-disable-unused";
		reg = <0>;
		power-domains = <&scpsys MT6897_POWER_DOMAIN_CAM_SUBC>;
	};

	disable-unused-pd-cam-vcore@0 {
		compatible = "mediatek,scpsys-disable-unused";
		reg = <0>;
		power-domains = <&scpsys MT6897_POWER_DOMAIN_CAM_VCORE>;
	};

	disable-unused-pd-cam-ccu@0 {
		compatible = "mediatek,scpsys-disable-unused";
		reg = <0>;
		power-domains = <&scpsys MT6897_POWER_DOMAIN_CAM_CCU>;
	};

	disable-unused-pd-cam-ccu-ao@0 {
		compatible = "mediatek,scpsys-disable-unused";
		reg = <0>;
		power-domains = <&scpsys MT6897_POWER_DOMAIN_CAM_CCU_AO>;
	};

	disable-unused-pd-mdp0-shutdown@0 {
		compatible = "mediatek,scpsys-disable-unused";
		reg = <0>;
		power-domains = <&scpsys MT6897_POWER_DOMAIN_MDP0_SHUTDOWN>;
	};

	disable-unused-pd-mdp1-shutdown@0 {
		compatible = "mediatek,scpsys-disable-unused";
		reg = <0>;
		power-domains = <&scpsys MT6897_POWER_DOMAIN_MDP1_SHUTDOWN>;
	};

	disable-unused-pd-dis0-shutdown@0 {
		compatible = "mediatek,scpsys-disable-unused";
		reg = <0>;
		power-domains = <&scpsys MT6897_POWER_DOMAIN_DIS0_SHUTDOWN>;
	};

	disable-unused-pd-dis1-shutdown@0 {
		compatible = "mediatek,scpsys-disable-unused";
		reg = <0>;
		power-domains = <&scpsys MT6897_POWER_DOMAIN_DIS1_SHUTDOWN>;
	};

	disable-unused-pd-ovl0-shutdown@0 {
		compatible = "mediatek,scpsys-disable-unused";
		reg = <0>;
		power-domains = <&scpsys MT6897_POWER_DOMAIN_OVL0_SHUTDOWN>;
	};

	disable-unused-pd-ovl1-shutdown@0 {
		compatible = "mediatek,scpsys-disable-unused";
		reg = <0>;
		power-domains = <&scpsys MT6897_POWER_DOMAIN_OVL1_SHUTDOWN>;
	};

	disable-unused-pd-mm-infra@0 {
		compatible = "mediatek,scpsys-disable-unused";
		reg = <0>;
		power-domains = <&scpsys MT6897_POWER_DOMAIN_MM_INFRA>;
	};

	disable-unused-pd-mm-proc-dormant@0 {
		compatible = "mediatek,scpsys-disable-unused";
		reg = <0>;
		power-domains = <&scpsys MT6897_POWER_DOMAIN_MM_PROC_DORMANT>;
	};

	disable-unused-pd-dp-tx@0 {
		compatible = "mediatek,scpsys-disable-unused";
		reg = <0>;
		power-domains = <&scpsys MT6897_POWER_DOMAIN_DP_TX>;
	};

	disable-unused-pd-csi-rx@0 {
		compatible = "mediatek,scpsys-disable-unused";
		reg = <0>;
		power-domains = <&scpsys MT6897_POWER_DOMAIN_CSI_RX>;
	};
};
